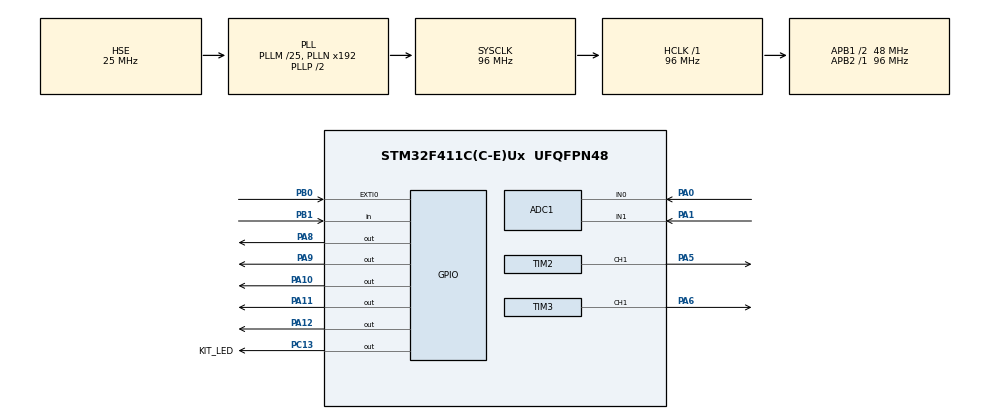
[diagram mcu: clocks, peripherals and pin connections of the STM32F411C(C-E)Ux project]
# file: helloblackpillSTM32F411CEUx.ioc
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ADC1.Channel-1\#ChannelRegularConversion=ADC_CHANNEL_0
ADC1.NbrOfConversionFlag=1
ADC1.Rank-1\#ChannelRegularConversion=1
ADC1.SamplingTime-1\#ChannelRegularConversion=ADC_SAMPLETIME_3CYCLES
ADC1.master=1
Mcu.Family=STM32F4
Mcu.Name=STM32F411C(C-E)Ux
Mcu.Package=UFQFPN48
NVIC.EXTI0_IRQn=true\:0\:0\:false\:false\:true\:true\:true\:true
NVIC.PriorityGroup=NVIC_PRIORITYGROUP_4
NVIC.TIM4_IRQn=true\:0\:0\:false\:false\:true\:true\:true\:true
PA0-WKUP.Signal=ADCx_IN0
PA1.Signal=ADCx_IN1
PA10.Signal=GPIO_Output
PA11.Signal=GPIO_Output
PA12.Signal=GPIO_Output
PA13.Mode=Serial_Wire
PA13.Signal=SYS_JTMS-SWDIO
PA14.Mode=Serial_Wire
PA14.Signal=SYS_JTCK-SWCLK
PA5.Signal=S_TIM2_CH1_ETR
PA6.Signal=S_TIM3_CH1
PA8.Signal=GPIO_Output
PA9.Signal=GPIO_Output
PB0.Signal=GPXTI0
PB1.Signal=GPIO_Input
PC13-ANTI_TAMP.GPIO_Label=KIT_LED
PC13-ANTI_TAMP.Signal=GPIO_Output
PC14-OSC32_IN.Mode=LSE-External-Oscillator
PC14-OSC32_IN.Signal=RCC_OSC32_IN
PC15-OSC32_OUT.Mode=LSE-External-Oscillator
PC15-OSC32_OUT.Signal=RCC_OSC32_OUT
PH0\ -\ OSC_IN.Mode=HSE-External-Oscillator
PH0\ -\ OSC_IN.Signal=RCC_OSC_IN
PH1\ -\ OSC_OUT.Mode=HSE-External-Oscillator
PH1\ -\ OSC_OUT.Signal=RCC_OSC_OUT
ProjectManager.HeapSize=0x200
ProjectManager.StackSize=0x400
ProjectManager.TargetToolchain=Makefile
RCC.48MHZClocksFreq_Value=48000000
RCC.AHBFreq_Value=96000000
RCC.APB1CLKDivider=RCC_HCLK_DIV2
RCC.APB1Freq_Value=48000000
RCC.APB1TimFreq_Value=96000000
RCC.APB2Freq_Value=96000000
RCC.APB2TimFreq_Value=96000000
RCC.CortexFreq_Value=96000000
RCC.HCLKFreq_Value=96000000
RCC.HSE_VALUE=25000000
RCC.HSI_VALUE=16000000
RCC.PLLM=25
RCC.PLLSourceVirtual=RCC_PLLSOURCE_HSE
RCC.SYSCLKFreq_VALUE=96000000
RCC.SYSCLKSource=RCC_SYSCLKSOURCE_PLLCLK
RCC.VCOOutputFreq_Value=192000000
SH.ADCx_IN0.0=ADC1_IN0,IN0
SH.ADCx_IN1.0=ADC1_IN1,IN1
SH.S_TIM2_CH1_ETR.0=TIM2_CH1,PWM Generation1 CH1
SH.S_TIM3_CH1.0=TIM3_CH1,PWM Generation1 CH1
TIM2.Channel-PWM\ Generation1\ CH1=TIM_CHANNEL_1
TIM2.Period=65535
TIM3.Channel-PWM\ Generation1\ CH1=TIM_CHANNEL_1
TIM4.Period=1800
TIM4.Prescaler=7200
VP_TIM4_VS_ClockSourceINT.Mode=Internal
board=custom

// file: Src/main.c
/* USER CODE BEGIN Header */
/**
  ******************************************************************************
  * @file           : main.c
  * @brief          : Main program body
  ******************************************************************************
  * @attention
  *
  * Copyright (c) 2025 STMicroelectronics.
  * All rights reserved.
  *
  * This software is licensed under terms that can be found in the LICENSE file
  * in the root directory of this software component.
  * If no LICENSE file comes with this software, it is provided AS-IS.
  *
  ******************************************************************************
  */
/* USER CODE END Header */
#include "main.h"
#include "math.h" // para calculos do projeto
#include "stdio.h" // para a funcao sprintf

ADC_HandleTypeDef hadc1;

TIM_HandleTypeDef htim2;
TIM_HandleTypeDef htim3;
TIM_HandleTypeDef htim4;

void SystemClock_Config(void);
static void MX_GPIO_Init(void);
static void MX_ADC1_Init(void);
static void MX_TIM3_Init(void);
static void MX_TIM4_Init(void);
static void MX_TIM2_Init(void);

/* definição das variáveis globais */
#define sensor_temperatura  ADC_CHANNEL_0
#define sensor_velocidade  ADC_CHANNEL_1

float TEMPERATURA=0;
float VELOCIDADE=0;

float fator_temperatura=0;
float fator_velocidade=0;

float read_TEMPERATURA[]={0,0,0,0,0};
float read_VELOCIDADE[]={0,0,0,0,0};

uint32_t flag_emergencia=0;

uint32_t i, read=0, option=0, flag_rede=0, j=0;

int tim_per2=7199;tim_psc2=10000,tim_pulse2=100;
int tim_per3=7199;tim_psc3=10000;tim_pulse3=100;

char buffer1[100],buffer2[100]; // serve para colocar texto, pode ser enviado por protocolo de comunicação

static void ADC_SET_CHANNEL (uint32_t channel)
{
    ADC_ChannelConfTypeDef sConfig = {0};
    sConfig.Channel = channel;
    sConfig.Rank = 1;
    sConfig.SamplingTime = ADC_SAMPLETIME_3CYCLES;
    if (HAL_ADC_ConfigChannel(&hadc1, &sConfig) != HAL_OK)
    {
      Error_Handler();
    }
}

int main(void)
{

  /* MCU Configuration--------------------------------------------------------*/

  /* Reset of all peripherals, Initializes the Flash interface and the Systick. */
  HAL_Init();

  /* Configure the system clock */
  SystemClock_Config();

  /* Initialize all configured peripherals */
  MX_GPIO_Init();
  MX_ADC1_Init();
  MX_TIM3_Init();
  MX_TIM4_Init();
  MX_TIM2_Init();
  //* tem que disparar o contador, se não ele permanece em idle */
  HAL_TIM_Base_Start_IT(&htim4);
  /* disparo do pwm */
  HAL_TIM_PWM_Start(&htim2, TIM_CHANNEL_1);
  HAL_TIM_PWM_Start(&htim3, TIM_CHANNEL_1);
  HAL_TIM_PWM_Start(&htim3, TIM_CHANNEL_2);
  /* Infinite loop */
  /* USER CODE BEGIN WHILE */
  while (1)
  {
    // leitura do canal AN0 do ADC para TEMPERATURA
    ADC_SET_CHANNEL(sensor_temperatura);
    for (i = 0; i <= 5; i++)
    {
      HAL_ADC_Start(&hadc1);
      HAL_ADC_PollForConversion(&hadc1,100);
      read = HAL_ADC_GetValue(&hadc1);
      read_TEMPERATURA[i] = (float)(read*3.3)/4095;

    }
    // leitura do canal AN1 do ADC para VELOCIDADE
    ADC_SET_CHANNEL(sensor_velocidade);
    for (i = 0; i <= 5; i++)
    {
      HAL_ADC_Start(&hadc1);
      HAL_ADC_PollForConversion(&hadc1,100);
      read = HAL_ADC_GetValue(&hadc1);
      read_VELOCIDADE[i] = (float)(read*3.3)/4095;
    }

    // SE ACIONAR V=0 NO PINO B1 , INCREMENTA O MENU;
    if(!HAL_GPIO_ReadPin(GPIOB,GPIO_PIN_1))
    {
      option++;
      HAL_Delay(50); // delay debouncing do botao
      // MAXIMO DE 3 OPCOES
      if(option==3)
      {
      option=0;
      }
    }
      // MENU PRINCIPAL COM AS OPCOES DE INFO DO MOTOR , TEMPERATURA E VELOCIDADE
      switch(option)
    {
        // INFOS DO MOTOR
      case 0:
      {
        // ENVIA A COMUNICACAO PARA UM DISPOSITIVO DE LEITURA DE SAIDA
          sprintf(buffer1,"MOTOR WEG W22 \n Potência: 5 cv \n Tensao: 380/660 V \n N POLOS: 4 \n ");
          sprintf(buffer2,"Rotacao Wn: 1800 RPM \n Frequencia: 60 Hz \n");
          break;
      }
        // INFO TEMPERATURA
        case 1:
      {
          sprintf(buffer1,"Temperatura do motor:");
          sprintf(buffer2," %f graus CELSIUS",TEMPERATURA);
          break;
      }
      // INFO VELOCIDADE
        case 2:
      {
          sprintf(buffer1,"Velocidade do motor:");
          sprintf(buffer2," %f RPM",VELOCIDADE);
          break;
      }
    }
    /* USER CODE END 3 */
    if(flag_rede==1)
    {
      for (i = 0; i < 2; i++)
      {
        HAL_GPIO_TogglePin(GPIOC, GPIO_PIN_13);
        HAL_Delay(10);
      }
      // CALCULOS
      // calculo da temperatura
      // transforma em graus celsius
      // sensor funciona de 0 a 50 GRAUS
      fator_temperatura= ((50-0)/3.3);
      //TEMPERATURA = read_TEMPERATURA*(50/4095);
      for (i = 0; i <= 5; i++)
        {
          TEMPERATURA = (read_TEMPERATURA[i]*fator_temperatura)/5+TEMPERATURA;
        }
      // CALCULOS
      // calculo da velocidade
      // transforma em rpm
      // sensor funciona de 0 a 2000 RPM
      fator_velocidade= ((2000-0)/3.3);
      //TEMPERATURA = read_TEMPERATURA*(50/4095);
      for (i = 0; i <= 5; i++)
        {
          VELOCIDADE = (read_VELOCIDADE[i]*fator_velocidade)/5+VELOCIDADE;
        }

        /*Acionamento de dois canais pwm*/
      /**
      fclock=96MHz
      Ttick=(PSC+1)/fclock
      Tpwm=(ARR+1)*Ttick
      fPWM= ftimer/(ARR+1)
      **/
      //PWM => TEMPERATURA
      // para 1s:
      //htim2.Init.Prescaler = 7199; //tim_psc2;
      //htim2.Init.Period = 10000; //tim_per2;
      //sConfigOC.Pulse = 100;

      TIM2->ARR = tim_per2; // Set the Autoreload value
      //TIM2->PSC = tim_psc2; // Set the Prescaler value
      htim2.Instance->CCR1 = (htim2.Instance->ARR*TEMPERATURA)/10000;

      //PWM => TEMPERATURA
      //tim_psc3=9600;
      //tim_per3=1000;

      TIM3->ARR = tim_per3; // Set the Autoreload value
      //TIM3->PSC = tim_psc3; // Set the Prescaler value
      htim3.Instance->CCR1 = (htim3.Instance->ARR*VELOCIDADE)/10000;

      // zera o flag, para o código entrar só depois de transcorrer os períodos de rede...
      flag_rede=0;
      j=0; // zera o contador de períodos da rede também

      TEMPERATURA=0;
      VELOCIDADE=0;
    }

  }

}

// EXTI Line9 External Interrupt ISR Handler CallBackFun
// BOTAO DE EMERGENCIA => SE O BOTAO FOR ACIONADO MUDA O ESTADO DO LED
void HAL_GPIO_EXTI_Callback(uint16_t GPIO_Pin)
{
  flag_emergencia=1;
  while (flag_emergencia==1)
  {
    HAL_GPIO_TogglePin(GPIOA, GPIO_PIN_8|GPIO_PIN_9|GPIO_PIN_10);
    tim_per2=0;
    tim_per3=0;
  }
}

/* rotina de interrupção do contador */
void HAL_TIM_PeriodElapsedCallback(TIM_HandleTypeDef* htim)
{
    j++;
    /* 20 LOOPS PARA REALIZAR MEDICOES NOVAMENTE */
    if(j>=10)
    {
      flag_rede=1;
    }
}

void SystemClock_Config(void)
{
  RCC_OscInitTypeDef RCC_OscInitStruct = {0};
  RCC_ClkInitTypeDef RCC_ClkInitStruct = {0};

  /** Configure the main internal regulator output voltage
  */
  __HAL_RCC_PWR_CLK_ENABLE();
  __HAL_PWR_VOLTAGESCALING_CONFIG(PWR_REGULATOR_VOLTAGE_SCALE1);

  /** Initializes the RCC Oscillators according to the specified parameters
  * in the RCC_OscInitTypeDef structure.
  */
  RCC_OscInitStruct.OscillatorType = RCC_OSCILLATORTYPE_HSE;
  RCC_OscInitStruct.HSEState = RCC_HSE_ON;
  RCC_OscInitStruct.PLL.PLLState = RCC_PLL_ON;
  RCC_OscInitStruct.PLL.PLLSource = RCC_PLLSOURCE_HSE;
  RCC_OscInitStruct.PLL.PLLM = 25;
  RCC_OscInitStruct.PLL.PLLN = 192;
  RCC_OscInitStruct.PLL.PLLP = RCC_PLLP_DIV2;
  RCC_OscInitStruct.PLL.PLLQ = 4;
  if (HAL_RCC_OscConfig(&RCC_OscInitStruct) != HAL_OK)
  {
    Error_Handler();
  }

  /** Initializes the CPU, AHB and APB buses clocks
  */
  RCC_ClkInitStruct.ClockType = RCC_CLOCKTYPE_HCLK|RCC_CLOCKTYPE_SYSCLK
                              |RCC_CLOCKTYPE_PCLK1|RCC_CLOCKTYPE_PCLK2;
  RCC_ClkInitStruct.SYSCLKSource = RCC_SYSCLKSOURCE_PLLCLK;
  RCC_ClkInitStruct.AHBCLKDivider = RCC_SYSCLK_DIV1;
  RCC_ClkInitStruct.APB1CLKDivider = RCC_HCLK_DIV2;
  RCC_ClkInitStruct.APB2CLKDivider = RCC_HCLK_DIV1;

  if (HAL_RCC_ClockConfig(&RCC_ClkInitStruct, FLASH_LATENCY_3) != HAL_OK)
  {
    Error_Handler();
  }
}

static void MX_ADC1_Init(void)
{

  ADC_ChannelConfTypeDef sConfig = {0};

  /** Configure the global features of the ADC (Clock, Resolution, Data Alignment and number of conversion)
  */
  hadc1.Instance = ADC1;
  hadc1.Init.ClockPrescaler = ADC_CLOCK_SYNC_PCLK_DIV4;
  hadc1.Init.Resolution = ADC_RESOLUTION_12B;
  hadc1.Init.ScanConvMode = DISABLE;
  hadc1.Init.ContinuousConvMode = DISABLE;
  hadc1.Init.DiscontinuousConvMode = DISABLE;
  hadc1.Init.ExternalTrigConvEdge = ADC_EXTERNALTRIGCONVEDGE_NONE;
  hadc1.Init.ExternalTrigConv = ADC_SOFTWARE_START;
  hadc1.Init.DataAlign = ADC_DATAALIGN_RIGHT;
  hadc1.Init.NbrOfConversion = 1;
  hadc1.Init.DMAContinuousRequests = DISABLE;
  hadc1.Init.EOCSelection = ADC_EOC_SINGLE_CONV;
  if (HAL_ADC_Init(&hadc1) != HAL_OK)
  {
    Error_Handler();
  }

  /** Configure for the selected ADC regular channel its corresponding rank in the sequencer and its sample time.
  */
  sConfig.Channel = ADC_CHANNEL_0;
  sConfig.Rank = 1;
  sConfig.SamplingTime = ADC_SAMPLETIME_3CYCLES;
  if (HAL_ADC_ConfigChannel(&hadc1, &sConfig) != HAL_OK)
  {
    Error_Handler();
  }

}

static void MX_TIM2_Init(void)
{

  TIM_MasterConfigTypeDef sMasterConfig = {0};
  TIM_OC_InitTypeDef sConfigOC = {0};

  htim2.Instance = TIM2;
  htim2.Init.Prescaler = tim_psc2;
  htim2.Init.CounterMode = TIM_COUNTERMODE_UP;
  htim2.Init.Period = tim_per2;
  htim2.Init.ClockDivision = TIM_CLOCKDIVISION_DIV1;
  htim2.Init.AutoReloadPreload = TIM_AUTORELOAD_PRELOAD_DISABLE;
  if (HAL_TIM_PWM_Init(&htim2) != HAL_OK)
  {
    Error_Handler();
  }
  sMasterConfig.MasterOutputTrigger = TIM_TRGO_RESET;
  sMasterConfig.MasterSlaveMode = TIM_MASTERSLAVEMODE_DISABLE;
  if (HAL_TIMEx_MasterConfigSynchronization(&htim2, &sMasterConfig) != HAL_OK)
  {
    Error_Handler();
  }
  sConfigOC.OCMode = TIM_OCMODE_PWM1;
  sConfigOC.Pulse = tim_pulse2;
  sConfigOC.OCPolarity = TIM_OCPOLARITY_HIGH;
  sConfigOC.OCFastMode = TIM_OCFAST_DISABLE;
  if (HAL_TIM_PWM_ConfigChannel(&htim2, &sConfigOC, TIM_CHANNEL_1) != HAL_OK)
  {
    Error_Handler();
  }
  HAL_TIM_MspPostInit(&htim2);

}

static void MX_TIM3_Init(void)
{

  TIM_MasterConfigTypeDef sMasterConfig = {0};
  TIM_OC_InitTypeDef sConfigOC = {0};

  htim3.Instance = TIM3;
  htim3.Init.Prescaler = tim_psc3;
  htim3.Init.CounterMode = TIM_COUNTERMODE_UP;
  htim3.Init.Period = tim_per3;
  htim3.Init.ClockDivision = TIM_CLOCKDIVISION_DIV1;
  htim3.Init.AutoReloadPreload = TIM_AUTORELOAD_PRELOAD_DISABLE;
  if (HAL_TIM_PWM_Init(&htim3) != HAL_OK)
  {
    Error_Handler();
  }
  sMasterConfig.MasterOutputTrigger = TIM_TRGO_RESET;
  sMasterConfig.MasterSlaveMode = TIM_MASTERSLAVEMODE_DISABLE;
  if (HAL_TIMEx_MasterConfigSynchronization(&htim3, &sMasterConfig) != HAL_OK)
  {
    Error_Handler();
  }
  sConfigOC.OCMode = TIM_OCMODE_PWM1;
  sConfigOC.Pulse = tim_pulse3; // 50% DO CICLO DE TRABALHO
  sConfigOC.OCPolarity = TIM_OCPOLARITY_HIGH;
  sConfigOC.OCFastMode = TIM_OCFAST_DISABLE;
  if (HAL_TIM_PWM_ConfigChannel(&htim3, &sConfigOC, TIM_CHANNEL_1) != HAL_OK)
  {
    Error_Handler();
  }
  /* USER CODE BEGIN TIM3_Init 2 */
   if (HAL_TIM_PWM_ConfigChannel(&htim3, &sConfigOC, TIM_CHANNEL_1) != HAL_OK)
   {
     Error_Handler();
   }
  /* USER CODE END TIM3_Init 2 */
  HAL_TIM_MspPostInit(&htim3);

}

static void MX_TIM4_Init(void)
{

  TIM_ClockConfigTypeDef sClockSourceConfig = {0};
  TIM_MasterConfigTypeDef sMasterConfig = {0};

  htim4.Instance = TIM4;
  htim4.Init.Prescaler = 7200;
  htim4.Init.CounterMode = TIM_COUNTERMODE_UP;
  htim4.Init.Period = 1800;
  htim4.Init.ClockDivision = TIM_CLOCKDIVISION_DIV1;
  htim4.Init.AutoReloadPreload = TIM_AUTORELOAD_PRELOAD_DISABLE;
  if (HAL_TIM_Base_Init(&htim4) != HAL_OK)
  {
    Error_Handler();
  }
  sClockSourceConfig.ClockSource = TIM_CLOCKSOURCE_INTERNAL;
  if (HAL_TIM_ConfigClockSource(&htim4, &sClockSourceConfig) != HAL_OK)
  {
    Error_Handler();
  }
  sMasterConfig.MasterOutputTrigger = TIM_TRGO_RESET;
  sMasterConfig.MasterSlaveMode = TIM_MASTERSLAVEMODE_DISABLE;
  if (HAL_TIMEx_MasterConfigSynchronization(&htim4, &sMasterConfig) != HAL_OK)
  {
    Error_Handler();
  }

}

static void MX_GPIO_Init(void)
{
  GPIO_InitTypeDef GPIO_InitStruct = {0};

  /* GPIO Ports Clock Enable */
  __HAL_RCC_GPIOC_CLK_ENABLE();
  __HAL_RCC_GPIOH_CLK_ENABLE();
  __HAL_RCC_GPIOA_CLK_ENABLE();
  __HAL_RCC_GPIOB_CLK_ENABLE();

  /*Configure GPIO pin Output Level */
  HAL_GPIO_WritePin(KIT_LED_GPIO_Port, KIT_LED_Pin, GPIO_PIN_RESET);

  /*Configure GPIO pin Output Level */
  HAL_GPIO_WritePin(GPIOA, GPIO_PIN_8|GPIO_PIN_9|GPIO_PIN_10|GPIO_PIN_11
                          |GPIO_PIN_12, GPIO_PIN_RESET);

  /*Configure GPIO pin : KIT_LED_Pin */
  GPIO_InitStruct.Pin = KIT_LED_Pin;
  GPIO_InitStruct.Mode = GPIO_MODE_OUTPUT_PP;
  GPIO_InitStruct.Pull = GPIO_NOPULL;
  GPIO_InitStruct.Speed = GPIO_SPEED_FREQ_LOW;
  HAL_GPIO_Init(KIT_LED_GPIO_Port, &GPIO_InitStruct);

  /*Configure GPIO pin : PB0 */
  GPIO_InitStruct.Pin = GPIO_PIN_0;
  GPIO_InitStruct.Mode = GPIO_MODE_IT_RISING;
  GPIO_InitStruct.Pull = GPIO_NOPULL;
  HAL_GPIO_Init(GPIOB, &GPIO_InitStruct);

  /*Configure GPIO pin : PB1 */
  GPIO_InitStruct.Pin = GPIO_PIN_1;
  GPIO_InitStruct.Mode = GPIO_MODE_INPUT;
  GPIO_InitStruct.Pull = GPIO_NOPULL;
  HAL_GPIO_Init(GPIOB, &GPIO_InitStruct);

  /*Configure GPIO pins : PA8 PA9 PA10 PA11
                           PA12 */
  GPIO_InitStruct.Pin = GPIO_PIN_8|GPIO_PIN_9|GPIO_PIN_10|GPIO_PIN_11
                          |GPIO_PIN_12;
  GPIO_InitStruct.Mode = GPIO_MODE_OUTPUT_PP;
  GPIO_InitStruct.Pull = GPIO_NOPULL;
  GPIO_InitStruct.Speed = GPIO_SPEED_FREQ_LOW;
  HAL_GPIO_Init(GPIOA, &GPIO_InitStruct);

  /* EXTI interrupt init*/
  HAL_NVIC_SetPriority(EXTI0_IRQn, 0, 0);
  HAL_NVIC_EnableIRQ(EXTI0_IRQn);

}

void Error_Handler(void)
{
   __disable_irq();
   while (1)
   {
   }
}
